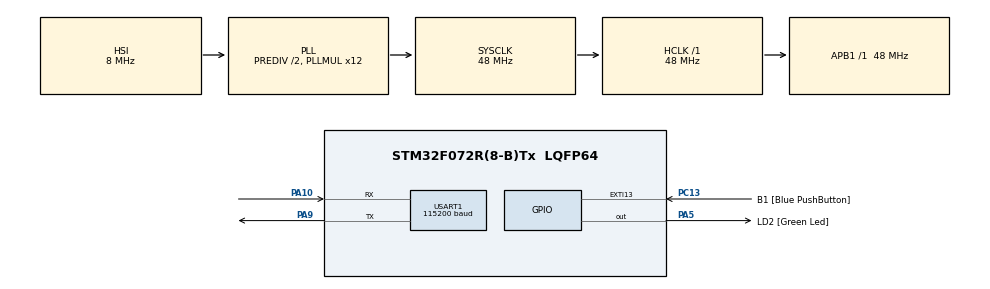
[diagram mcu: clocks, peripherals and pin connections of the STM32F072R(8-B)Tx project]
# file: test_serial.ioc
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Mcu.Family=STM32F0
Mcu.Name=STM32F072R(8-B)Tx
Mcu.Package=LQFP64
PA10.Mode=Asynchronous
PA10.Signal=USART1_RX
PA13.GPIO_Label=TMS
PA13.Signal=SYS_SWDIO
PA14.GPIO_Label=TCK
PA14.Signal=SYS_SWCLK
PA2.GPIO_Label=USART_TX
PA2.GPIO_Mode=GPIO_MODE_AF_PP
PA2.GPIO_PuPd=GPIO_NOPULL
PA2.GPIO_Speed=GPIO_SPEED_FREQ_LOW
PA2.Signal=USART2_TX
PA3.GPIO_Label=USART_RX
PA3.GPIO_Mode=GPIO_MODE_AF_PP
PA3.GPIO_PuPd=GPIO_NOPULL
PA3.GPIO_Speed=GPIO_SPEED_FREQ_LOW
PA3.Signal=USART2_RX
PA5.GPIO_Label=LD2 [Green Led]
PA5.GPIO_Mode=GPIO_MODE_OUTPUT_PP
PA5.GPIO_PuPd=GPIO_NOPULL
PA5.GPIO_Speed=GPIO_SPEED_FREQ_LOW
PA5.Signal=GPIO_Output
PA9.Mode=Asynchronous
PA9.Signal=USART1_TX
PC13.GPIO_Label=B1 [Blue PushButton]
PC13.GPIO_ModeDefaultEXTI=GPIO_MODE_IT_FALLING
PC13.Signal=GPXTI13
PC14-OSC32_IN.Signal=RCC_OSC32_IN
PC15-OSC32_OUT.Signal=RCC_OSC32_OUT
PF0-OSC_IN.Signal=RCC_OSC_IN
PF1-OSC_OUT.Signal=RCC_OSC_OUT
ProjectManager.HeapSize=0x200
ProjectManager.StackSize=0x400
ProjectManager.TargetToolchain=STM32CubeIDE
RCC.AHBFreq_Value=48000000
RCC.APB1Freq_Value=48000000
RCC.APB1TimFreq_Value=48000000
RCC.FLatency-AdvancedSettings=FLASH_LATENCY_1
RCC.HCLKFreq_Value=48000000
RCC.PLLDivider=RCC_PREDIV_DIV2
RCC.PLLMUL=RCC_PLL_MUL12
RCC.SYSCLKFreq_VALUE=48000000
RCC.SYSCLKSource=RCC_SYSCLKSOURCE_PLLCLK
USART1.BaudRate=115200
USART1.VirtualMode-Asynchronous=VM_ASYNC
board=NUCLEO-F072RB

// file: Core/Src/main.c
/* USER CODE BEGIN Header */
/**
  ******************************************************************************
  * @file           : main.c
  * @brief          : Main program body
  ******************************************************************************
  * @attention
  *
  * <h2><center>&copy; Copyright (c) 2021 STMicroelectronics.
  * All rights reserved.</center></h2>
  *
  * This software component is licensed by ST under BSD 3-Clause license,
  * the "License"; You may not use this file except in compliance with the
  * License. You may obtain a copy of the License at:
  *                        opensource.org/licenses/BSD-3-Clause
  *
  ******************************************************************************
  */
/* USER CODE END Header */
#include "main.h"
#include "usart.h"
#include "gpio.h"

void SystemClock_Config(void);

int main(void)
{

  /* MCU Configuration--------------------------------------------------------*/

  /* Reset of all peripherals, Initializes the Flash interface and the Systick. */
  HAL_Init();

  /* Configure the system clock */
  SystemClock_Config();

  /* Initialize all configured peripherals */
  MX_GPIO_Init();
  MX_USART1_UART_Init();

  /* Infinite loop */
  /* USER CODE BEGIN WHILE */

  while (1)
  {
	  char buffer[7];
	  buffer[0] = 'A';
	  buffer[1] = 'b';
	  buffer[2] = 'C';
	  buffer[3] = 'A';
	  buffer[4] = 'b';
	  buffer[5] = 'C';
	  buffer[7] = '\n';
	  buffer[6] = '\r';
	  HAL_UART_Transmit (&huart1, buffer , sizeof(buffer) , 100);

	  HAL_Delay(1000);
    /* USER CODE END WHILE */

  }
}

void SystemClock_Config(void)
{
  RCC_OscInitTypeDef RCC_OscInitStruct = {0};
  RCC_ClkInitTypeDef RCC_ClkInitStruct = {0};
  RCC_PeriphCLKInitTypeDef PeriphClkInit = {0};

  /** Initializes the RCC Oscillators according to the specified parameters
  * in the RCC_OscInitTypeDef structure.
  */
  RCC_OscInitStruct.OscillatorType = RCC_OSCILLATORTYPE_HSI;
  RCC_OscInitStruct.HSIState = RCC_HSI_ON;
  RCC_OscInitStruct.HSICalibrationValue = RCC_HSICALIBRATION_DEFAULT;
  RCC_OscInitStruct.PLL.PLLState = RCC_PLL_ON;
  RCC_OscInitStruct.PLL.PLLSource = RCC_PLLSOURCE_HSI;
  RCC_OscInitStruct.PLL.PLLMUL = RCC_PLL_MUL12;
  RCC_OscInitStruct.PLL.PREDIV = RCC_PREDIV_DIV2;
  if (HAL_RCC_OscConfig(&RCC_OscInitStruct) != HAL_OK)
  {
    Error_Handler();
  }
  /** Initializes the CPU, AHB and APB buses clocks
  */
  RCC_ClkInitStruct.ClockType = RCC_CLOCKTYPE_HCLK|RCC_CLOCKTYPE_SYSCLK
                              |RCC_CLOCKTYPE_PCLK1;
  RCC_ClkInitStruct.SYSCLKSource = RCC_SYSCLKSOURCE_PLLCLK;
  RCC_ClkInitStruct.AHBCLKDivider = RCC_SYSCLK_DIV1;
  RCC_ClkInitStruct.APB1CLKDivider = RCC_HCLK_DIV1;

  if (HAL_RCC_ClockConfig(&RCC_ClkInitStruct, FLASH_LATENCY_1) != HAL_OK)
  {
    Error_Handler();
  }
  PeriphClkInit.PeriphClockSelection = RCC_PERIPHCLK_USART1;
  PeriphClkInit.Usart1ClockSelection = RCC_USART1CLKSOURCE_PCLK1;
  if (HAL_RCCEx_PeriphCLKConfig(&PeriphClkInit) != HAL_OK)
  {
    Error_Handler();
  }
}

void Error_Handler(void)
{
  __disable_irq();
  while (1)
  {
  }
}

/************************ (C) COPYRIGHT STMicroelectronics *****END OF FILE****/
